# STM32F7x3 register map
File version: 1.3
CPU: CM7 r0p1, little endian, MPU, FPU, 4 interrupt priority bits
Registers are 32-bit, read-write, reset 0x0 unless marked. A register's access mark holds for its fields unless they carry their own. Offsets are from the block's base; [hi:lo] are bit positions; {n}, {i} and the like mark numbered series.

## EXTI — External interrupt/event controller
Base 0x40013C00
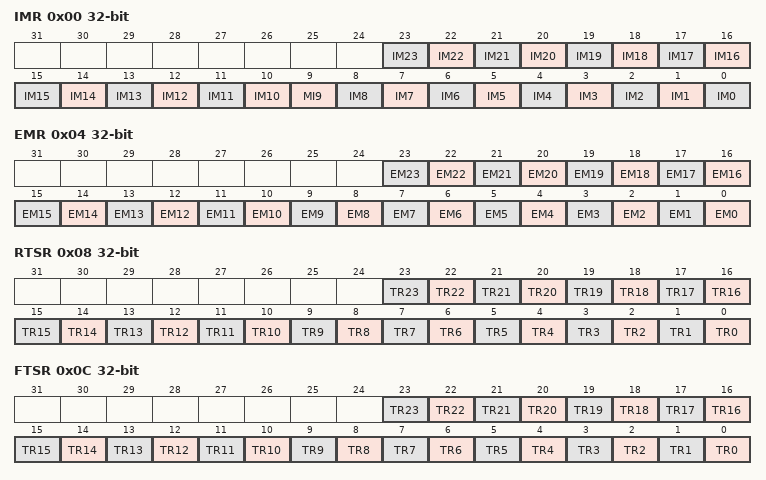
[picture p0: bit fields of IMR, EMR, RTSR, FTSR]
0x00 IMR — Interrupt mask register (EXTI_IMR)
  [n] IM{n} (n=10..23) — Interrupt Mask on line {n}
  [9] MI9 — Interrupt Mask on line 9
  [n] IM{n} (n=0..8) — Interrupt Mask on line {n}
0x04 EMR — Event mask register (EXTI_EMR)
  [n] EM{n} (n=0..23) — Event Mask on line {n}
0x08 RTSR — Rising Trigger selection register (EXTI_RTSR)
  [n] TR{n} (n=0..23) — Rising trigger event configuration of line {n}
0x0C FTSR — Falling Trigger selection register (EXTI_FTSR)
  [n] TR{n} (n=0..23) — Falling trigger event configuration of line {n}
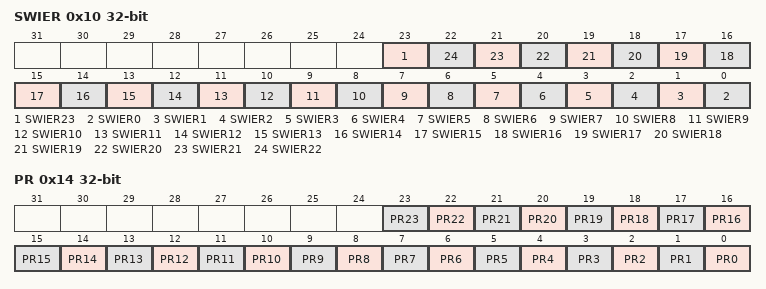
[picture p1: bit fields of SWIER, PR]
0x10 SWIER — Software interrupt event register (EXTI_SWIER)
  [23] SWIER23 — Software Interrupt on line 22
  [n] SWIER{n} (n=0..22) — Software Interrupt on line {n}
0x14 PR — Pending register (EXTI_PR)
  [n] PR{n} (n=0..23) — Pending bit {n}

## FLASH
Base 0x40023C00
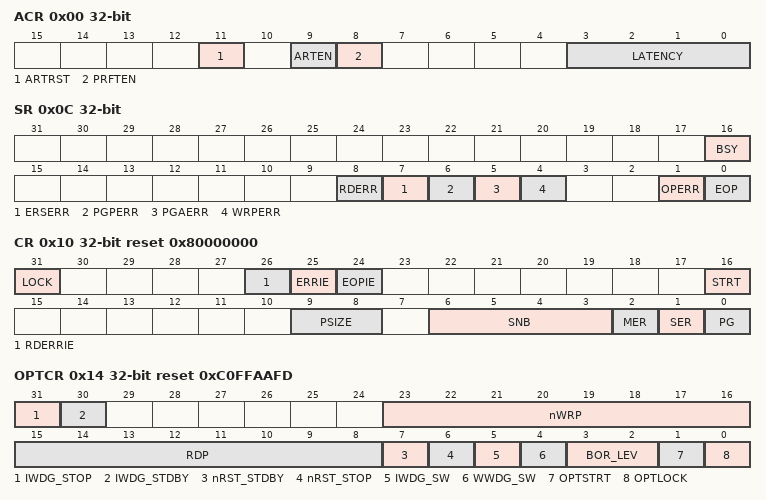
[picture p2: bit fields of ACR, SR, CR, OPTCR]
0x00 ACR — Flash access control register
  [11] ARTRST — ART Accelerator reset
  [9] ARTEN — ART Accelerator Enable
  [8] PRFTEN — Prefetch enable
  [3:0] LATENCY
0x04 KEYR wo — Flash key register
  [31:0] KEY — FPEC key
0x08 OPTKEYR wo — Flash option key register
  [31:0] OPTKEYR — Option byte key
0x0C SR access per field — Status register
  [16] BSY ro — Busy
  [8] RDERR rw
  [7] ERSERR rw — Erase Sequence Error
  [6] PGPERR rw — Programming parallelism error
  [5] PGAERR rw — Programming alignment error
  [4] WRPERR rw — Write protection error
  [1] OPERR rw — Operation error
  [0] EOP rw — End of operation
0x10 CR reset 0x80000000 — Control register
  [31] LOCK
  [26] RDERRIE — PCROP error interrupt enable
  [25] ERRIE — Error interrupt enable
  [24] EOPIE — End of operation interrupt enable
  [16] STRT — Start
  [9:8] PSIZE — Program size
  [6:3] SNB — Sector number
  [2] MER — Mass Erase of sectors 0 to 11
  [1] SER — Sector Erase
  [0] PG — Programming
0x14 OPTCR reset 0xC0FFAAFD — Flash option control register
  [31] IWDG_STOP — Independent watchdog counter freeze in Stop mode
  [30] IWDG_STDBY — Independent watchdog counter freeze in standby mode
  [23:16] nWRP — Not write protect
  [15:8] RDP — Read protect
  [7] nRST_STDBY — nRST_STDBY User option bytes
  [6] nRST_STOP — nRST_STOP User option bytes
  [5] IWDG_SW — WDG_SW User option bytes
  [4] WWDG_SW — User option bytes
  [3:2] BOR_LEV — BOR reset Level
  [1] OPTSTRT — Option start
  [0] OPTLOCK — Option lock
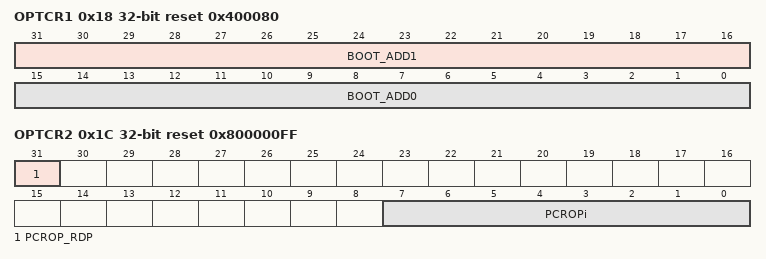
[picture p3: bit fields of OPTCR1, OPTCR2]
0x18 OPTCR1 reset 0x400080 — Flash option control register 1
  [31:16] BOOT_ADD1 — Boot base address when Boot pin =1
  [15:0] BOOT_ADD0 — Boot base address when Boot pin =0
0x1C OPTCR2 reset 0x800000FF — Flash option control register
  [31] PCROP_RDP — PCROP zone preserved when RDP level decreased
  [7:0] PCROPi — PCROP option byte

## TIM9 — General purpose timers
Base 0x40014000
Same registers: TIM12 0x40001800
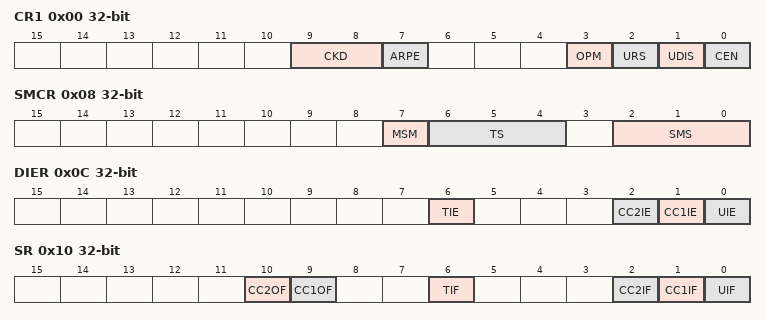
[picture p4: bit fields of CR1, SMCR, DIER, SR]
0x00 CR1 — control register 1
  [9:8] CKD — Clock division
  [7] ARPE — Auto-reload preload enable
  [3] OPM — One-pulse mode
  [2] URS — Update request source
  [1] UDIS — Update disable
  [0] CEN — Counter enable
0x08 SMCR — slave mode control register
  [7] MSM — Master/Slave mode
  [6:4] TS — Trigger selection
  [2:0] SMS — Slave mode selection
0x0C DIER — DMA/Interrupt enable register
  [6] TIE — Trigger interrupt enable
  [2] CC2IE — Capture/Compare 2 interrupt enable
  [1] CC1IE — Capture/Compare 1 interrupt enable
  [0] UIE — Update interrupt enable
0x10 SR — status register
  [10] CC2OF — Capture/compare 2 overcapture flag
  [9] CC1OF — Capture/Compare 1 overcapture flag
  [6] TIF — Trigger interrupt flag
  [2] CC2IF — Capture/Compare 2 interrupt flag
  [1] CC1IF — Capture/compare 1 interrupt flag
  [0] UIF — Update interrupt flag
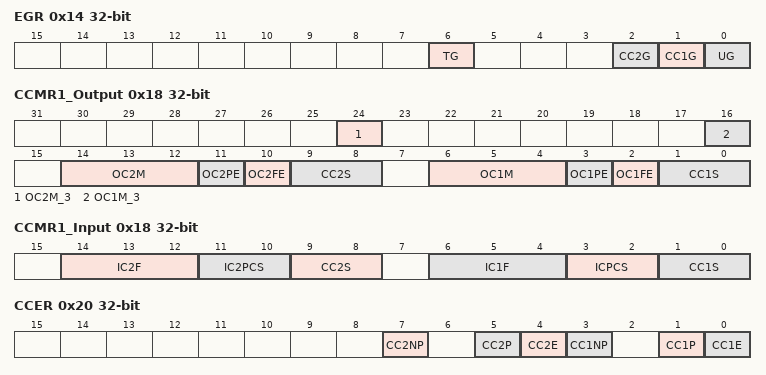
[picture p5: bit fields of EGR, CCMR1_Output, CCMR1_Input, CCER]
0x14 EGR wo — event generation register
  [6] TG — Trigger generation
  [2] CC2G — Capture/compare 2 generation
  [1] CC1G — Capture/compare 1 generation
  [0] UG — Update generation
0x18 CCMR1_Output — capture/compare mode register 1 (output mode)
  [24] OC2M_3 — Output Compare 2 mode - bit 3
  [16] OC1M_3 — Output Compare 1 mode - bit 3
  [14:12] OC2M — Output Compare 2 mode
  [11] OC2PE — Output Compare 2 preload enable
  [10] OC2FE — Output Compare 2 fast enable
  [9:8] CC2S — Capture/Compare 2 selection
  [6:4] OC1M — Output Compare 1 mode
  [3] OC1PE — Output Compare 1 preload enable
  [2] OC1FE — Output Compare 1 fast enable
  [1:0] CC1S — Capture/Compare 1 selection
0x18 CCMR1_Input (alternate view of CCMR1_Output) — capture/compare mode register 1 (input mode)
  [14:12] IC2F — Input capture 2 filter
  [11:10] IC2PCS — Input capture 2 prescaler
  [9:8] CC2S — Capture/Compare 2 selection
  [6:4] IC1F — Input capture 1 filter
  [3:2] ICPCS — Input capture 1 prescaler
  [1:0] CC1S — Capture/Compare 1 selection
0x20 CCER — capture/compare enable register
  [7] CC2NP — Capture/Compare 2 output Polarity
  [5] CC2P — Capture/Compare 2 output Polarity
  [4] CC2E — Capture/Compare 2 output enable
  [3] CC1NP — Capture/Compare 1 output Polarity
  [1] CC1P — Capture/Compare 1 output Polarity
  [0] CC1E — Capture/Compare 1 output enable
0x24 CNT — counter
  [15:0] CNT — counter value
0x28 PSC — prescaler
  [15:0] PSC — Prescaler value
0x2C ARR — auto-reload register
  [15:0] ARR — Auto-reload value
0x34 CCR1 — capture/compare register 1
  [15:0] CCR1 — Capture/Compare 1 value
0x38 CCR2 — capture/compare register 2
  [15:0] CCR2 — Capture/Compare 2 value
